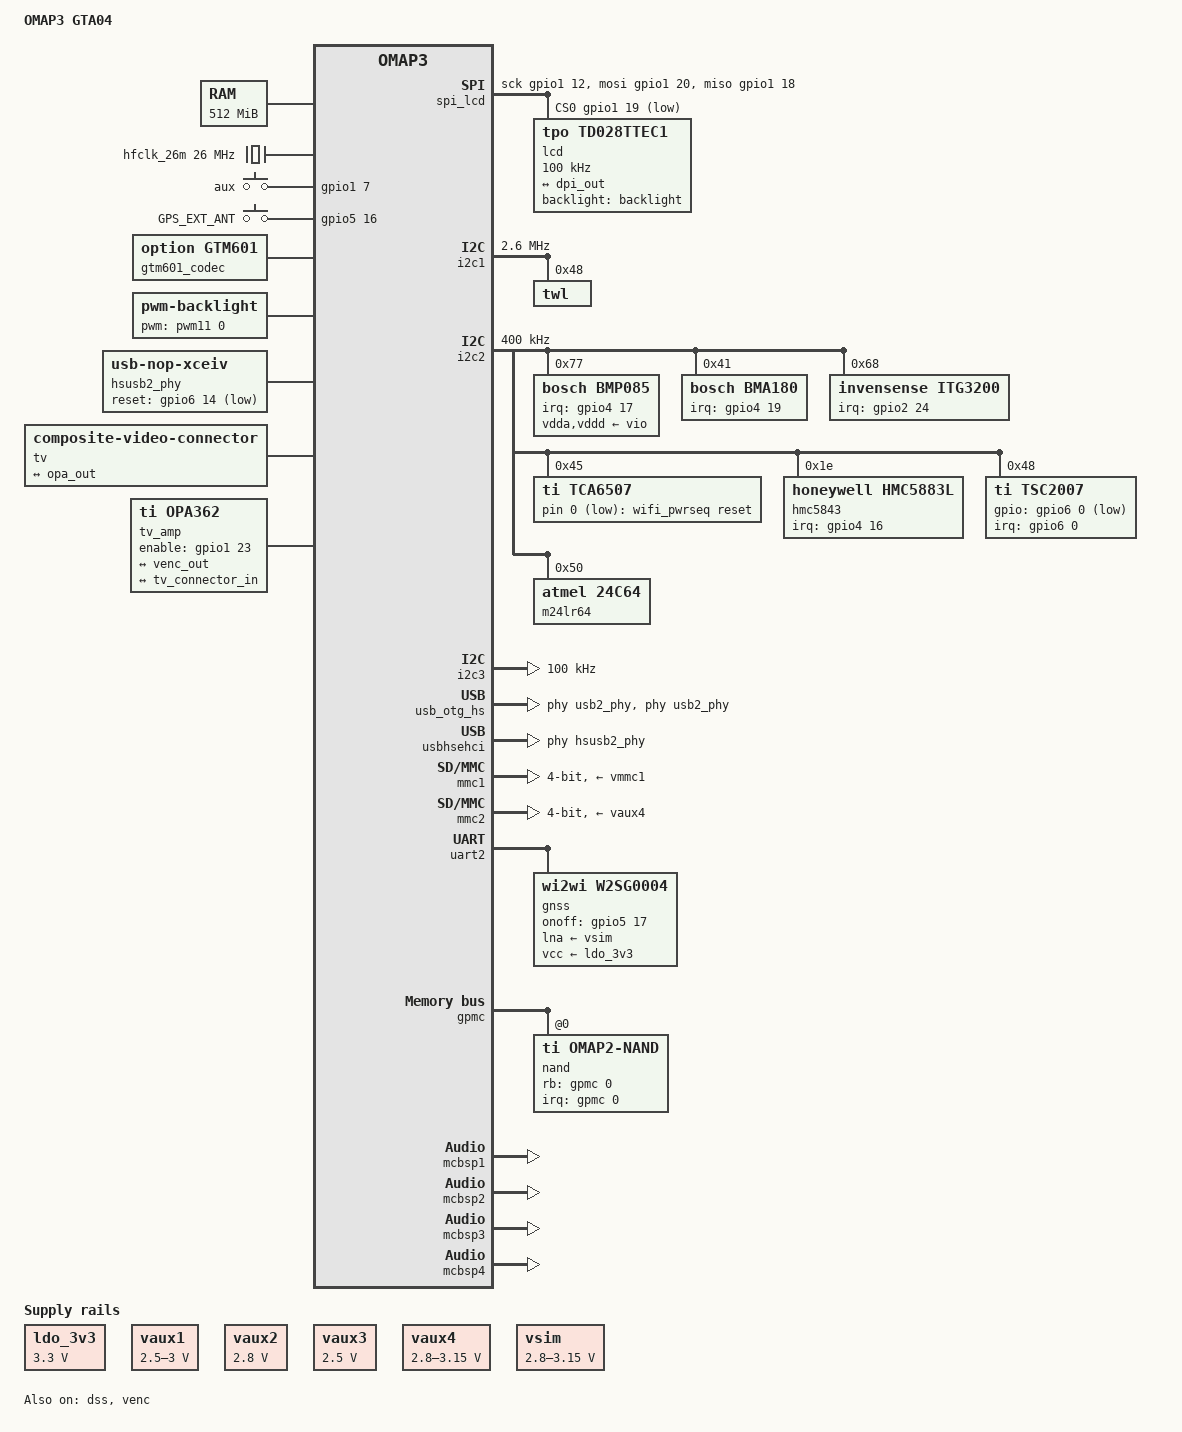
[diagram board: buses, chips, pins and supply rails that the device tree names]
/dts-v1/;
#include "omap36xx.dtsi"
#include <dt-bindings/input/input.h>
/ {
	model = "OMAP3 GTA04";
	compatible = "goldelico,gta04", "ti,omap3630", "ti,omap36xx", "ti,omap3";
	cpus {
		cpu@0 {
			cpu0-supply = <&vcc>;
		};
	};
	memory@80000000 {
		device_type = "memory";
		reg = <0x80000000 0x20000000>;  
	};
	chosen {
		stdout-path = &uart3;
	};
	aliases {
		display0 = &lcd;
		display1 = &tv0;
		/delete-property/ mmc2;
		/delete-property/ mmc3;
	};
	ldo_3v3: fixedregulator {
		compatible = "regulator-fixed";
		regulator-name = "ldo_3v3";
		regulator-min-microvolt = <3300000>;
		regulator-max-microvolt = <3300000>;
		regulator-always-on;
	};
	hfclk_26m: oscillator {
		#clock-cells = <0>;
		compatible = "fixed-clock";
		clock-frequency = <26000000>;
	};
	gpio-keys {
		compatible = "gpio-keys";
		aux-button {
			label = "aux";
			linux,code = <KEY_PHONE>;
			gpios = <&gpio1 7 GPIO_ACTIVE_HIGH>;
			wakeup-source;
		};
	};
	antenna-detect {
		compatible = "gpio-keys";
		gps_antenna_button: gps-antenna-button {
			label = "GPS_EXT_ANT";
			linux,input-type = <EV_SW>;
			linux,code = <SW_LINEIN_INSERT>;
			gpios = <&gpio5 16 GPIO_ACTIVE_HIGH>;  
			interrupt-parent = <&gpio5>;
			interrupts = <16 IRQ_TYPE_EDGE_BOTH>;
			debounce-interval = <10>;
			wakeup-source;
		};
	};
	sound {
		compatible = "ti,omap-twl4030";
		ti,model = "gta04";
		ti,mcbsp = <&mcbsp2>;
	};
	sound_telephony {
		compatible = "simple-audio-card";
		simple-audio-card,name = "GTA04 voice";
		simple-audio-card,bitclock-master = <&telephony_link_master>;
		simple-audio-card,frame-master = <&telephony_link_master>;
		simple-audio-card,format = "i2s";
		simple-audio-card,bitclock-inversion;
		simple-audio-card,frame-inversion;
		simple-audio-card,cpu {
			sound-dai = <&mcbsp4>;
		};
		telephony_link_master: simple-audio-card,codec {
			sound-dai = <&gtm601_codec>;
		};
	};
	gtm601_codec: gsm_codec {
		compatible = "option,gtm601";
		#sound-dai-cells = <0>;
	};
	spi_lcd: spi {
		compatible = "spi-gpio";
		#address-cells = <0x1>;
		#size-cells = <0x0>;
		pinctrl-names = "default";
		pinctrl-0 = <&spi_gpio_pins>;
		sck-gpios = <&gpio1 12 GPIO_ACTIVE_HIGH>;
		miso-gpios = <&gpio1 18 GPIO_ACTIVE_HIGH>;
		mosi-gpios = <&gpio1 20 GPIO_ACTIVE_HIGH>;
		cs-gpios = <&gpio1 19 GPIO_ACTIVE_LOW>;
		num-chipselects = <1>;
		lcd: td028ttec1@0 {
			compatible = "tpo,td028ttec1";
			reg = <0>;
			spi-max-frequency = <100000>;
			spi-cpol;
			spi-cpha;
			backlight = <&backlight>;
			label = "lcd";
			port {
				lcd_in: endpoint {
					remote-endpoint = <&dpi_out>;
				};
			};
		};
	};
	backlight: backlight {
		compatible = "pwm-backlight";
		pwms = <&pwm11 0 12000000 0>;
		pwm-names = "backlight";
		brightness-levels = <0 11 20 30 40 50 60 70 80 90 100>;
		default-brightness-level = <9>;	 
		pinctrl-names = "default";
		pinctrl-0 = <&backlight_pins>;
	};
	pwm11: pwm-11 {
		compatible = "ti,omap-dmtimer-pwm";
		ti,timers = <&timer11>;
		#pwm-cells = <3>;
		ti,clock-source = <0x01>;
	};
	hsusb2_phy: hsusb2-phy-pins {
		compatible = "usb-nop-xceiv";
		reset-gpios = <&gpio6 14 GPIO_ACTIVE_LOW>;
		#phy-cells = <0>;
	};
	tv0: connector {
		compatible = "composite-video-connector";
		label = "tv";
		port {
			tv_connector_in: endpoint {
				remote-endpoint = <&opa_out>;
			};
		};
	};
	tv_amp: opa362 {
		compatible = "ti,opa362";
		enable-gpios = <&gpio1 23 GPIO_ACTIVE_HIGH>;	 
		ports {
			#address-cells = <1>;
			#size-cells = <0>;
			port@0 {
				reg = <0>;
				opa_in: endpoint {
					remote-endpoint = <&venc_out>;
				};
			};
			port@1 {
				reg = <1>;
				opa_out: endpoint {
					remote-endpoint = <&tv_connector_in>;
				};
			};
		};
	};
	wifi_pwrseq: wifi_pwrseq {
		compatible = "mmc-pwrseq-simple";
		reset-gpios = <&tca6507 0 GPIO_ACTIVE_LOW>;	 
	};
	pinmux@48002274 {
		compatible = "pinctrl-single";
		reg = <0x48002274 4>;    
		#address-cells = <1>;
		#size-cells = <0>;
		pinctrl-single,bit-per-mux;
		pinctrl-single,register-width = <32>;
		pinctrl-single,function-mask = <0x7>;	 
		#pinctrl-cells = <2>;
		pinctrl-names = "default";
		pinctrl-0 = <&mcbsp1_devconf0_pins>;
		mcbsp1_devconf0_pins: mcbsp1-devconf0-pins {
			pinctrl-single,bits = <0x00 0x08 0x1c>;	 
		};
	};
	pinmux@480022d8 {
		compatible = "pinctrl-single";
		reg = <0x480022d8 4>;	 
		#address-cells = <1>;
		#size-cells = <0>;
		pinctrl-single,bit-per-mux;
		pinctrl-single,register-width = <32>;
		pinctrl-single,function-mask = <0x81>;	 
		#pinctrl-cells = <2>;
		pinctrl-names = "default";
		pinctrl-0 = <&tv_acbias_devconf1_pins>;
		tv_acbias_devconf1_pins: tv-acbias-devconf1-pins {
			pinctrl-single,bits = <0x00 0x40800 0x40800>;	 
		};
	};
};
&omap3_pmx_wkup {
	gpio1_pins: gpio1-pins {
		pinctrl-single,pins = <
			OMAP3_WKUP_IOPAD(0x2a14, PIN_INPUT | PIN_OFF_WAKEUPENABLE | MUX_MODE4)  
			OMAP3_WKUP_IOPAD(0x2a1a, PIN_INPUT | PIN_OFF_WAKEUPENABLE | MUX_MODE4)  
		>;
	};
};
&omap3_pmx_core {
	pinctrl-names = "default";
	pinctrl-0 = <
			&hsusb2_pins
	>;
	hsusb2_pins: hsusb2-pins {
		pinctrl-single,pins = <
			OMAP3_CORE1_IOPAD(0x21d4, PIN_INPUT_PULLDOWN | MUX_MODE3)	 
			OMAP3_CORE1_IOPAD(0x21d6, PIN_INPUT_PULLDOWN | MUX_MODE3)	 
			OMAP3_CORE1_IOPAD(0x21d8, PIN_INPUT_PULLDOWN | MUX_MODE3)	 
			OMAP3_CORE1_IOPAD(0x21da, PIN_INPUT_PULLDOWN | MUX_MODE3)	 
			OMAP3_CORE1_IOPAD(0x21dc, PIN_INPUT_PULLDOWN | MUX_MODE3)	 
			OMAP3_CORE1_IOPAD(0x21de, PIN_INPUT_PULLDOWN | MUX_MODE3)	 
		>;
	};
	uart1_pins: uart1-pins {
		pinctrl-single,pins = <
			OMAP3_CORE1_IOPAD(0x2182, PIN_INPUT | MUX_MODE0)		 
			OMAP3_CORE1_IOPAD(0x217c, PIN_OUTPUT | MUX_MODE0)		 
		>;
	};
	uart2_pins: uart2-pins {
		pinctrl-single,pins = <
			OMAP3_CORE1_IOPAD(0x217a, PIN_INPUT | MUX_MODE0)		 
			OMAP3_CORE1_IOPAD(0x2178, PIN_OUTPUT | MUX_MODE0)		 
		>;
	};
	uart3_pins: uart3-pins {
		pinctrl-single,pins = <
			OMAP3_CORE1_IOPAD(0x219e, PIN_INPUT | MUX_MODE0)		 
			OMAP3_CORE1_IOPAD(0x21a0, PIN_OUTPUT | MUX_MODE0)		 
		>;
	};
	mmc1_pins: mmc1-pins {
		pinctrl-single,pins = <
			OMAP3_CORE1_IOPAD(0x2144, PIN_INPUT_PULLUP | MUX_MODE0)		 
			OMAP3_CORE1_IOPAD(0x2146, PIN_INPUT_PULLUP | MUX_MODE0)		 
			OMAP3_CORE1_IOPAD(0x2148, PIN_INPUT_PULLUP | MUX_MODE0)		 
			OMAP3_CORE1_IOPAD(0x214a, PIN_INPUT_PULLUP | MUX_MODE0)		 
			OMAP3_CORE1_IOPAD(0x214c, PIN_INPUT_PULLUP | MUX_MODE0)		 
			OMAP3_CORE1_IOPAD(0x214e, PIN_INPUT_PULLUP | MUX_MODE0)		 
		>;
	};
	backlight_pins: backlight-pinmux-pins {
		pinctrl-single,pins = <
			OMAP3_CORE1_IOPAD(0x20ba, MUX_MODE3)		 
		>;
	};
	dss_dpi_pins: dss-dpi-pins {
		pinctrl-single,pins = <
			OMAP3_CORE1_IOPAD(0x20d4, PIN_OUTPUT | MUX_MODE0)    
			OMAP3_CORE1_IOPAD(0x20d6, PIN_OUTPUT | MUX_MODE0)    
			OMAP3_CORE1_IOPAD(0x20d8, PIN_OUTPUT | MUX_MODE0)    
			OMAP3_CORE1_IOPAD(0x20da, PIN_OUTPUT | MUX_MODE0)    
			OMAP3_CORE1_IOPAD(0x20dc, PIN_OUTPUT | MUX_MODE0)    
			OMAP3_CORE1_IOPAD(0x20de, PIN_OUTPUT | MUX_MODE0)    
			OMAP3_CORE1_IOPAD(0x20e0, PIN_OUTPUT | MUX_MODE0)    
			OMAP3_CORE1_IOPAD(0x20e2, PIN_OUTPUT | MUX_MODE0)    
			OMAP3_CORE1_IOPAD(0x20e4, PIN_OUTPUT | MUX_MODE0)    
			OMAP3_CORE1_IOPAD(0x20e6, PIN_OUTPUT | MUX_MODE0)    
			OMAP3_CORE1_IOPAD(0x20e8, PIN_OUTPUT | MUX_MODE0)    
			OMAP3_CORE1_IOPAD(0x20ea, PIN_OUTPUT | MUX_MODE0)    
			OMAP3_CORE1_IOPAD(0x20ec, PIN_OUTPUT | MUX_MODE0)    
			OMAP3_CORE1_IOPAD(0x20ee, PIN_OUTPUT | MUX_MODE0)    
			OMAP3_CORE1_IOPAD(0x20f0, PIN_OUTPUT | MUX_MODE0)    
			OMAP3_CORE1_IOPAD(0x20f2, PIN_OUTPUT | MUX_MODE0)    
			OMAP3_CORE1_IOPAD(0x20f4, PIN_OUTPUT | MUX_MODE0)    
			OMAP3_CORE1_IOPAD(0x20f6, PIN_OUTPUT | MUX_MODE0)    
			OMAP3_CORE1_IOPAD(0x20f8, PIN_OUTPUT | MUX_MODE0)    
			OMAP3_CORE1_IOPAD(0x20fa, PIN_OUTPUT | MUX_MODE0)    
			OMAP3_CORE1_IOPAD(0x20fc, PIN_OUTPUT | MUX_MODE0)    
			OMAP3_CORE1_IOPAD(0x20fe, PIN_OUTPUT | MUX_MODE0)    
			OMAP3_CORE1_IOPAD(0x2100, PIN_OUTPUT | MUX_MODE0)    
			OMAP3_CORE1_IOPAD(0x2102, PIN_OUTPUT | MUX_MODE0)    
			OMAP3_CORE1_IOPAD(0x2104, PIN_OUTPUT | MUX_MODE0)    
			OMAP3_CORE1_IOPAD(0x2106, PIN_OUTPUT | MUX_MODE0)    
			OMAP3_CORE1_IOPAD(0x2108, PIN_OUTPUT | MUX_MODE0)    
			OMAP3_CORE1_IOPAD(0x210a, PIN_OUTPUT | MUX_MODE0)    
		>;
	};
	gps_pins: gps-pins {
		pinctrl-single,pins = <
			OMAP3_CORE1_IOPAD(0x2176, PIN_OUTPUT_PULLDOWN | MUX_MODE4)  
		>;
	};
	hdq_pins: hdq-pins {
		pinctrl-single,pins = <
			OMAP3_CORE1_IOPAD(0x21c6, PIN_INPUT_PULLUP | MUX_MODE0)  
		>;
	};
	bmp085_pins: bmp085-pins {
		pinctrl-single,pins = <
			OMAP3_CORE1_IOPAD(0x2136, PIN_INPUT_PULLUP | MUX_MODE4)  
		>;
	};
	bma180_pins: bma180-pins {
		pinctrl-single,pins = <
			OMAP3_CORE1_IOPAD(0x213a, PIN_INPUT_PULLUP | MUX_MODE4)  
		>;
	};
	itg3200_pins: itg3200-pins {
		pinctrl-single,pins = <
			OMAP3_CORE1_IOPAD(0x20b8, PIN_INPUT_PULLUP | MUX_MODE4)  
		>;
	};
	hmc5843_pins: hmc5843-pins {
		pinctrl-single,pins = <
			OMAP3_CORE1_IOPAD(0x2134, PIN_INPUT_PULLUP | MUX_MODE4)  
		>;
	};
	penirq_pins: penirq-pins {
		pinctrl-single,pins = <
			OMAP3_CORE1_IOPAD(0x2194, PIN_INPUT_PULLUP | MUX_MODE4)  
		>;
	};
	camera_pins: camera-pins {
		pinctrl-single,pins = <
			OMAP3_CORE1_IOPAD(0x210c, PIN_INPUT_PULLDOWN | MUX_MODE0)  
			OMAP3_CORE1_IOPAD(0x210e, PIN_INPUT_PULLDOWN | MUX_MODE0)  
			OMAP3_CORE1_IOPAD(0x2110, PIN_OUTPUT | MUX_MODE0)  
			OMAP3_CORE1_IOPAD(0x2112, PIN_INPUT_PULLDOWN | MUX_MODE0)  
			OMAP3_CORE1_IOPAD(0x2114, PIN_OUTPUT | MUX_MODE4)  
			OMAP3_CORE1_IOPAD(0x2116, PIN_INPUT_PULLDOWN | MUX_MODE0)  
			OMAP3_CORE1_IOPAD(0x2118, PIN_INPUT_PULLDOWN | MUX_MODE0)  
			OMAP3_CORE1_IOPAD(0x211a, PIN_INPUT_PULLDOWN | MUX_MODE0)  
			OMAP3_CORE1_IOPAD(0x211c, PIN_INPUT_PULLDOWN | MUX_MODE0)  
			OMAP3_CORE1_IOPAD(0x211e, PIN_INPUT_PULLDOWN | MUX_MODE0)  
			OMAP3_CORE1_IOPAD(0x2120, PIN_INPUT_PULLDOWN | MUX_MODE0)  
			OMAP3_CORE1_IOPAD(0x2122, PIN_INPUT_PULLDOWN | MUX_MODE0)  
			OMAP3_CORE1_IOPAD(0x2124, PIN_INPUT_PULLDOWN | MUX_MODE0)  
			OMAP3_CORE1_IOPAD(0x2126, PIN_INPUT_PULLDOWN | MUX_MODE0)  
			OMAP3_CORE1_IOPAD(0x2128, PIN_INPUT_PULLDOWN | MUX_MODE0)  
			OMAP3_CORE1_IOPAD(0x212a, PIN_INPUT_PULLDOWN | MUX_MODE0)  
			OMAP3_CORE1_IOPAD(0x212c, PIN_INPUT_PULLDOWN | MUX_MODE0)  
			OMAP3_CORE1_IOPAD(0x212e, PIN_OUTPUT | MUX_MODE0)  
			OMAP3_CORE1_IOPAD(0x2130, PIN_OUTPUT | MUX_MODE4)  
			OMAP3_CORE1_IOPAD(0x2132, PIN_INPUT_PULLDOWN | MUX_MODE4)  
		>;
	};
	mcbsp1_pins: mcbsp1-pins {
		pinctrl-single,pins = <
			OMAP3_CORE1_IOPAD(0x218c, PIN_INPUT | MUX_MODE4)	 
			OMAP3_CORE1_IOPAD(0x218e, PIN_OUTPUT | MUX_MODE0)	 
			OMAP3_CORE1_IOPAD(0x2190, PIN_OUTPUT | MUX_MODE0)	 
			OMAP3_CORE1_IOPAD(0x2192, PIN_INPUT | MUX_MODE0)	 
			OMAP3_CORE1_IOPAD(0x2196, PIN_INPUT | MUX_MODE0)	 
			OMAP3_CORE1_IOPAD(0x2198, PIN_INPUT | MUX_MODE0)	 
		>;
	};
	mcbsp2_pins: mcbsp2-pins {
		pinctrl-single,pins = <
			OMAP3_CORE1_IOPAD(0x213c, PIN_INPUT | MUX_MODE0)	 
			OMAP3_CORE1_IOPAD(0x213e, PIN_INPUT | MUX_MODE0)	 
			OMAP3_CORE1_IOPAD(0x2140, PIN_INPUT | MUX_MODE0)	 
			OMAP3_CORE1_IOPAD(0x2142, PIN_OUTPUT | MUX_MODE0)	 
		>;
	};
	mcbsp3_pins: mcbsp3-pins {
		pinctrl-single,pins = <
			OMAP3_CORE1_IOPAD(0x216c, PIN_OUTPUT | MUX_MODE0)	 
			OMAP3_CORE1_IOPAD(0x216e, PIN_INPUT | MUX_MODE0)	 
			OMAP3_CORE1_IOPAD(0x2170, PIN_INPUT | MUX_MODE0)	 
			OMAP3_CORE1_IOPAD(0x2172, PIN_INPUT | MUX_MODE0)	 
		>;
	};
	mcbsp4_pins: mcbsp4-pins {
		pinctrl-single,pins = <
			OMAP3_CORE1_IOPAD(0x2184, PIN_INPUT_PULLDOWN | MUX_MODE0)	 
			OMAP3_CORE1_IOPAD(0x2186, PIN_INPUT_PULLDOWN | MUX_MODE0)	 
			OMAP3_CORE1_IOPAD(0x218a, PIN_INPUT_PULLDOWN | MUX_MODE0)	 
		>;
	};
};
&omap3_pmx_core2 {
	pinctrl-names = "default";
	pinctrl-0 = <
			&hsusb2_2_pins
	>;
	hsusb2_2_pins: hsusb2-2-pins {
		pinctrl-single,pins = <
			OMAP3630_CORE2_IOPAD(0x25f0, PIN_OUTPUT | MUX_MODE3)		 
			OMAP3630_CORE2_IOPAD(0x25f2, PIN_OUTPUT | MUX_MODE3)		 
			OMAP3630_CORE2_IOPAD(0x25f4, PIN_INPUT_PULLDOWN | MUX_MODE3)	 
			OMAP3630_CORE2_IOPAD(0x25f6, PIN_INPUT_PULLDOWN | MUX_MODE3)	 
			OMAP3630_CORE2_IOPAD(0x25f8, PIN_INPUT_PULLDOWN | MUX_MODE3)	 
			OMAP3630_CORE2_IOPAD(0x25fa, PIN_INPUT_PULLDOWN | MUX_MODE3)	 
		>;
	};
	spi_gpio_pins: spi-gpio-pinmux-pins {
		pinctrl-single,pins = <
			OMAP3630_CORE2_IOPAD(0x25d8, PIN_OUTPUT | MUX_MODE4)  
			OMAP3630_CORE2_IOPAD(0x25e6, PIN_OUTPUT | MUX_MODE4)  
			OMAP3630_CORE2_IOPAD(0x25e8, PIN_OUTPUT | MUX_MODE4)  
			OMAP3630_CORE2_IOPAD(0x25e4, PIN_INPUT | MUX_MODE4)  
		>;
	};
};
&i2c1 {
	clock-frequency = <2600000>;
	twl: twl@48 {
		reg = <0x48>;
		interrupts = <7>;  
		interrupt-parent = <&intc>;
		clocks = <&hfclk_26m>;
		clock-names = "fck";
		twl_audio: audio {
			compatible = "ti,twl4030-audio";
			ti,enable-vibra = <1>;
			codec {
				ti,ramp_delay_value = <3>;
			};
		};
		twl_power: power {
			compatible = "ti,twl4030-power-idle";
			ti,system-power-controller;
		};
	};
};
#include "twl4030.dtsi"
#include "twl4030_omap3.dtsi"
&i2c2 {
	clock-frequency = <400000>;
	bmp085@77 {
		compatible = "bosch,bmp085";
		reg = <0x77>;
		pinctrl-names = "default";
		pinctrl-0 = <&bmp085_pins>;
		interrupt-parent = <&gpio4>;
		interrupts = <17 IRQ_TYPE_EDGE_RISING>;  
		vdda-supply = <&vio>;
		vddd-supply = <&vio>;
	};
	bma180@41 {
		compatible = "bosch,bma180";
		reg = <0x41>;
		pinctrl-names = "default";
		pinctrl-0 = <&bma180_pins>;
		interrupt-parent = <&gpio4>;
		interrupts = <19 IRQ_TYPE_LEVEL_HIGH>;  
	};
	itg3200@68 {
		compatible = "invensense,itg3200";
		reg = <0x68>;
		pinctrl-names = "default";
		pinctrl-0 = <&itg3200_pins>;
		interrupt-parent = <&gpio2>;
		interrupts = <24 IRQ_TYPE_EDGE_FALLING>;  
	};
	tca6507: tca6507@45 {
		compatible = "ti,tca6507";
		#address-cells = <1>;
		#size-cells = <0>;
		reg = <0x45>;
		gpio-controller;
		#gpio-cells = <2>;
		gta04_led0: led@0 {
			label = "gta04:red:aux";
			reg = <0x0>;
		};
		gta04_led1: led@1 {
			label = "gta04:green:aux";
			reg = <0x1>;
		};
		gta04_led3: led@3 {
			label = "gta04:red:power";
			reg = <0x3>;
			linux,default-trigger = "default-on";
		};
		gta04_led4: led@4 {
			label = "gta04:green:power";
			reg = <0x4>;
		};
		wifi_reset: led@6 {
			reg = <0x6>;
			compatible = "gpio";
		};
	};
	hmc5843@1e {
		compatible = "honeywell,hmc5883l";
		reg = <0x1e>;
		pinctrl-names = "default";
		pinctrl-0 = <&hmc5843_pins>;
		interrupt-parent = <&gpio4>;
		interrupts = <16 IRQ_TYPE_EDGE_FALLING>;	 
	};
	tsc2007@48 {
		compatible = "ti,tsc2007";
		reg = <0x48>;
		pinctrl-names = "default";
		pinctrl-0 = <&penirq_pins>;
		interrupt-parent = <&gpio6>;
		interrupts = <0 IRQ_TYPE_EDGE_FALLING>;  
		gpios = <&gpio6 0 GPIO_ACTIVE_LOW>;	 
		ti,x-plate-ohms = <600>;
		touchscreen-size-x = <480>;
		touchscreen-size-y = <640>;
		touchscreen-max-pressure = <1000>;
		touchscreen-fuzz-x = <3>;
		touchscreen-fuzz-y = <8>;
		touchscreen-fuzz-pressure = <10>;
		touchscreen-inverted-y;
	};
	m24lr64@50 {
		compatible = "atmel,24c64";
		reg = <0x50>;
	};
};
&i2c3 {
	clock-frequency = <100000>;
};
&mcspi1 {
	status = "disabled";
};
&mcspi2 {
	status = "disabled";
};
&mcspi3 {
	status = "disabled";
};
&mcspi4 {
	status = "disabled";
};
&usb_otg_hs {
	interface-type = <0>;
	usb-phy = <&usb2_phy>;
	phys = <&usb2_phy>;
	phy-names = "usb2-phy";
	mode = <3>;
	power = <50>;
};
&usbhshost {
	port2-mode = "ehci-phy";
};
&usbhsehci {
	phys = <0 &hsusb2_phy>;
};
&mmc1 {
	pinctrl-names = "default";
	pinctrl-0 = <&mmc1_pins>;
	vmmc-supply = <&vmmc1>;
	bus-width = <4>;
	ti,non-removable;
	broken-cd;	 
};
&mmc2 {
	vmmc-supply = <&vaux4>;
	bus-width = <4>;
	ti,non-removable;
	cap-power-off-card;
	mmc-pwrseq = <&wifi_pwrseq>;
};
&mmc3 {
	status = "disabled";
};
#define BIT(x) (1 << (x))
&twl_gpio {
	ti,pullups = <BIT(2)>;
	ti,pulldowns = <(BIT(0) | BIT(1) | BIT(6) | BIT(7) | BIT(8) |
			 BIT(13) | BIT(15) | BIT(16) | BIT(17))>;
};
&twl_keypad {
	status = "disabled";
};
&gpio1 {
	pinctrl-names = "default";
	pinctrl-0 = <&gpio1_pins>;
};
&uart1 {
	pinctrl-names = "default";
	pinctrl-0 = <&uart1_pins>;
};
&uart2 {
	pinctrl-names = "default";
	pinctrl-0 = <&uart2_pins>;
	gnss: gnss {
		compatible = "wi2wi,w2sg0004";
		pinctrl-names = "default";
		pinctrl-0 = <&gps_pins>;
		sirf,onoff-gpios = <&gpio5 17 GPIO_ACTIVE_HIGH>;
		lna-supply = <&vsim>;
		vcc-supply = <&ldo_3v3>;
	};
};
&uart3 {
	pinctrl-names = "default";
	pinctrl-0 = <&uart3_pins>;
	interrupts-extended = <&intc 74 &omap3_pmx_core OMAP3_UART3_RX>;
};
&charger {
	ti,bb-uvolt = <3200000>;
	ti,bb-uamp = <150>;
};
&vaux1 {
	regulator-min-microvolt = <2500000>;
	regulator-max-microvolt = <3000000>;
};
&vaux2 {
	regulator-min-microvolt = <2800000>;
	regulator-max-microvolt = <2800000>;
	regulator-always-on;	 
};
&vaux3 {
	regulator-min-microvolt = <2500000>;
	regulator-max-microvolt = <2500000>;
};
&vaux4 {
	regulator-min-microvolt = <2800000>;
	regulator-max-microvolt = <3150000>;
};
&vsim {
	regulator-min-microvolt = <2800000>;
	regulator-max-microvolt = <3150000>;
};
&vpll2 {
	regulator-always-on;
};
&dss {
	pinctrl-names = "default";
	pinctrl-0 = < &dss_dpi_pins >;
	status = "okay";
	vdds_dsi-supply = <&vpll2>;
	port {
		dpi_out: endpoint {
			remote-endpoint = <&lcd_in>;
			data-lines = <24>;
		};
	};
};
&venc {
	status = "okay";
	vdda-supply = <&vdac>;
	port {
		venc_out: endpoint {
			remote-endpoint = <&opa_in>;
			ti,channels = <1>;
			ti,invert-polarity;
		};
	};
};
&gpmc {
	ranges = <0 0 0x30000000 0x1000000>;  
	nand@0,0 {
		compatible = "ti,omap2-nand";
		reg = <0 0 4>;  
		interrupt-parent = <&gpmc>;
		interrupts = <0 IRQ_TYPE_NONE>,  
			     <1 IRQ_TYPE_NONE>;	 
		ti,nand-ecc-opt = "ham1";
		rb-gpios = <&gpmc 0 GPIO_ACTIVE_HIGH>;  
		nand-bus-width = <16>;
		#address-cells = <1>;
		#size-cells = <1>;
		gpmc,device-width = <2>;
		gpmc,cs-on-ns = <0>;
		gpmc,cs-rd-off-ns = <44>;
		gpmc,cs-wr-off-ns = <44>;
		gpmc,adv-on-ns = <6>;
		gpmc,adv-rd-off-ns = <34>;
		gpmc,adv-wr-off-ns = <44>;
		gpmc,oe-off-ns = <54>;
		gpmc,we-off-ns = <40>;
		gpmc,access-ns = <64>;
		gpmc,rd-cycle-ns = <82>;
		gpmc,wr-cycle-ns = <82>;
		gpmc,wr-access-ns = <40>;
		gpmc,wr-data-mux-bus-ns = <0>;
		gpmc,sync-clk-ps = <0>;
		x-loader@0 {
			label = "X-Loader";
			reg = <0 0x80000>;
		};
		bootloaders@80000 {
			label = "U-Boot";
			reg = <0x80000 0x1c0000>;
		};
		bootloaders_env@240000 {
			label = "U-Boot Env";
			reg = <0x240000 0x40000>;
		};
		kernel@280000 {
			label = "Kernel";
			reg = <0x280000 0x600000>;
		};
		filesystem@880000 {
			label = "File System";
			reg = <0x880000 0>;	 
		};
	};
};
&mcbsp1 {  
	status = "okay";
	#sound-dai-cells = <0>;
	pinctrl-names = "default";
	pinctrl-0 = <&mcbsp1_pins>;
};
&mcbsp2 {  
	status = "okay";
	pinctrl-names = "default";
	pinctrl-0 = <&mcbsp2_pins>;
};
&mcbsp3 {  
	status = "okay";
	#sound-dai-cells = <0>;
	pinctrl-names = "default";
	pinctrl-0 = <&mcbsp3_pins>;
};
&mcbsp4 {  
	status = "okay";
	#sound-dai-cells = <0>;
	pinctrl-names = "default";
	pinctrl-0 = <&mcbsp4_pins>;
};
&hdqw1w {
	pinctrl-names = "default";
	pinctrl-0 = <&hdq_pins>;
};
&isp {
	ports {
		port@0 {
			reg = <0>;
			parallel_ep: endpoint {
				ti,isp-clock-divisor = <1>;
				ti,strobe-mode;
				bus-width = <8>; 
				data-shift = <2>;  
				hsync-active = <0>;  
				vsync-active = <1>;  
				data-active = <1>; 
				pclk-sample = <1>; 
			};
		};
	};
};
